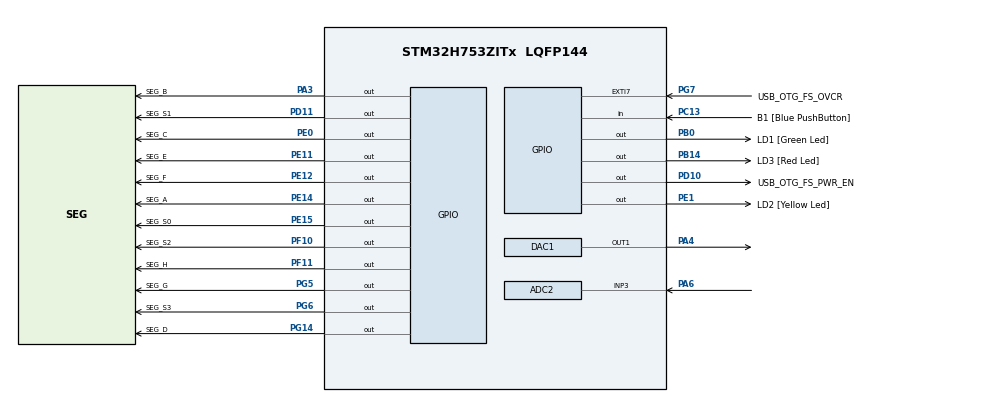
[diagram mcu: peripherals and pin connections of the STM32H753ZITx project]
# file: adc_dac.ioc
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ADC2.Channel-0\#ChannelRegularConversion=ADC_CHANNEL_3
ADC2.ExternalTrigConv=ADC_EXTERNALTRIG_T1_TRGO
ADC2.NbrOfConversionFlag=1
ADC2.OffsetNumber-0\#ChannelRegularConversion=ADC_OFFSET_NONE
ADC2.OffsetSignedSaturation-0\#ChannelRegularConversion=DISABLE
ADC2.Rank-0\#ChannelRegularConversion=1
ADC2.SamplingTime-0\#ChannelRegularConversion=ADC_SAMPLETIME_64CYCLES_5
CORTEX_M7.CPU_DCache=Disabled
CORTEX_M7.CPU_ICache=Disabled
CORTEX_M7.MPU_Control=__NULL
CORTEX_M7.default_mode_Activation=0
DAC1.DAC_Channel-DAC_OUT1=DAC_CHANNEL_1
Mcu.Family=STM32H7
Mcu.Name=STM32H753ZITx
Mcu.Package=LQFP144
NVIC.ADC_IRQn=true\:0\:0\:false\:false\:true\:true\:true\:true
NVIC.PriorityGroup=NVIC_PRIORITYGROUP_4
PA1.Signal=ETH_REF_CLK
PA11.Signal=USB_OTG_FS_DM
PA12.Signal=USB_OTG_FS_DP
PA2.Signal=ETH_MDIO
PA3.GPIO_Label=SEG_B
PA3.Signal=GPIO_Output
PA4.Signal=COMP_DAC11_group
PA6.Signal=ADCx_INP3
PA7.Signal=ETH_CRS_DV
PA8.Signal=USB_OTG_FS_SOF
PA9.Signal=USB_OTG_FS_VBUS
PB0.GPIO_Label=LD1 [Green Led]
PB0.Signal=GPIO_Output
PB13.Signal=ETH_TXD1
PB14.GPIO_Label=LD3 [Red Led]
PB14.Signal=GPIO_Output
PC1.Signal=ETH_MDC
PC13.GPIO_Label=B1 [Blue PushButton]
PC13.Signal=GPIO_Input
PC14-OSC32_IN\ (OSC32_IN).Mode=LSE-External-Oscillator
PC14-OSC32_IN\ (OSC32_IN).Signal=RCC_OSC32_IN
PC15-OSC32_OUT\ (OSC32_OUT).Mode=LSE-External-Oscillator
PC15-OSC32_OUT\ (OSC32_OUT).Signal=RCC_OSC32_OUT
PC4.Signal=ETH_RXD0
PC5.Signal=ETH_RXD1
PD10.GPIO_Label=USB_OTG_FS_PWR_EN
PD10.Signal=GPIO_Output
PD11.GPIO_Label=SEG_S1
PD11.Signal=GPIO_Output
PD8.GPIO_Label=STLINK_RX
PD8.Signal=USART3_TX
PD9.GPIO_Label=STLINK_TX
PD9.Signal=USART3_RX
PE0.GPIO_Label=SEG_C
PE0.Signal=GPIO_Output
PE1.GPIO_Label=LD2 [Yellow Led]
PE1.Signal=GPIO_Output
PE11.GPIO_Label=SEG_E
PE11.Signal=GPIO_Output
PE12.GPIO_Label=SEG_F
PE12.Signal=GPIO_Output
PE14.GPIO_Label=SEG_A
PE14.Signal=GPIO_Output
PE15.GPIO_Label=SEG_S0
PE15.Signal=GPIO_Output
PF10.GPIO_Label=SEG_S2
PF10.Signal=GPIO_Output
PF11.GPIO_Label=SEG_H
PF11.Signal=GPIO_Output
PG11.Signal=ETH_TX_EN
PG13.Signal=ETH_TXD0
PG14.GPIO_Label=SEG_D
PG14.Signal=GPIO_Output
PG5.GPIO_Label=SEG_G
PG5.Signal=GPIO_Output
PG6.GPIO_Label=SEG_S3
PG6.Signal=GPIO_Output
PG7.GPIO_Label=USB_OTG_FS_OVCR
PG7.Signal=GPXTI7
PH0-OSC_IN\ (PH0).Mode=HSE-External-Clock-Source
PH0-OSC_IN\ (PH0).Signal=RCC_OSC_IN
PH1-OSC_OUT\ (PH1).Signal=RCC_OSC_OUT
ProjectManager.HeapSize=0x200
ProjectManager.StackSize=0x400
ProjectManager.TargetToolchain=STM32CubeIDE
RCC.ADCFreq_Value=80000000
RCC.APB1Freq_Value=100000000
RCC.APB2Freq_Value=100000000
RCC.APB3Freq_Value=100000000
RCC.APB4Freq_Value=100000000
RCC.CortexFreq_Value=200000000
RCC.D1PPRE=RCC_APB3_DIV2
RCC.D2PPRE1=RCC_APB1_DIV2
RCC.D2PPRE2=RCC_APB2_DIV2
RCC.D3PPRE=RCC_APB4_DIV2
RCC.DIVM1=4
RCC.DIVM2=4
RCC.DIVN1=25
RCC.DIVN2=10
RCC.HCLKFreq_Value=200000000
RCC.PLL2FRACN=0
RCC.PLL3FRACN=0
RCC.PLLFRACN=0
RCC.PWR_Regulator_Voltage_Scale=PWR_REGULATOR_VOLTAGE_SCALE2
RCC.SYSCLKFreq_VALUE=200000000
RCC.SYSCLKSource=RCC_SYSCLKSOURCE_PLLCLK
RCC.USBFreq_Value=200000000
SH.ADCx_INP3.0=ADC2_INP3,IN3-Single-Ended
SH.COMP_DAC11_group.0=DAC1_OUT1,DAC_OUT1
TIM1.AutoReloadPreload=TIM_AUTORELOAD_PRELOAD_ENABLE
TIM1.Channel-Output\ Compare1\ No\ Output=TIM_CHANNEL_1
TIM1.Period=10
TIM1.Prescaler=64000
TIM1.TIM_MasterOutputTrigger=TIM_TRGO_UPDATE
VP_MEMORYMAP_VS_MEMORYMAP.Mode=CurAppReg
VP_TIM1_VS_ClockSourceINT.Mode=Internal
VP_TIM1_VS_no_output1.Mode=Output Compare1 No Output
board=custom

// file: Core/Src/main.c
/* USER CODE BEGIN Header */
/**
  ******************************************************************************
  * @file           : main.c
  * @brief          : Main program body
  ******************************************************************************
  * @attention
  *
  * Copyright (c) 2024 STMicroelectronics.
  * All rights reserved.
  *
  * This software is licensed under terms that can be found in the LICENSE file
  * in the root directory of this software component.
  * If no LICENSE file comes with this software, it is provided AS-IS.
  *
  ******************************************************************************
  */
/* USER CODE END Header */
#include "main.h"

/* USER CODE BEGIN Includes */
#include "segment.h"
/* USER CODE END Includes */

ADC_HandleTypeDef hadc2;

DAC_HandleTypeDef hdac1;

TIM_HandleTypeDef htim1;

/* USER CODE BEGIN PV */
segment_t *seg_handle;
/* USER CODE END PV */

void SystemClock_Config(void);
static void MX_GPIO_Init(void);
static void MX_ADC2_Init(void);
static void MX_DAC1_Init(void);
static void MX_TIM1_Init(void);

int main(void)
{

  /* MCU Configuration--------------------------------------------------------*/

  /* Reset of all peripherals, Initializes the Flash interface and the Systick. */
  HAL_Init();

  /* Configure the system clock */
  SystemClock_Config();

  /* Initialize all configured peripherals */
  MX_GPIO_Init();
  MX_ADC2_Init();
  MX_DAC1_Init();
  MX_TIM1_Init();
  /* USER CODE BEGIN 2 */
  //開啟ADC 功能
  HAL_ADC_Start_IT(&hadc2);
  //開啟PWM 作為ADC 觸發源
  HAL_TIM_PWM_Start(&htim1, TIM_CHANNEL_1);
  //設定七段顯示器顯示ADC 值
  seg_handle = segment_new(4);
  segment_num_set(seg_handle, 0);
  /* USER CODE END 2 */

  /* Infinite loop */
  while (1)
  {

    /* USER CODE BEGIN 3 */
	  __disable_irq();
	  segment_flush(seg_handle);
	  __enable_irq();
	  HAL_Delay(3);
  }
  /* USER CODE END 3 */
}

void SystemClock_Config(void)
{
  RCC_OscInitTypeDef RCC_OscInitStruct = {0};
  RCC_ClkInitTypeDef RCC_ClkInitStruct = {0};

  /** Supply configuration update enable
  */
  HAL_PWREx_ConfigSupply(PWR_LDO_SUPPLY);

  /** Configure the main internal regulator output voltage
  */
  __HAL_PWR_VOLTAGESCALING_CONFIG(PWR_REGULATOR_VOLTAGE_SCALE2);

  while(!__HAL_PWR_GET_FLAG(PWR_FLAG_VOSRDY)) {}

  /** Initializes the RCC Oscillators according to the specified parameters
  * in the RCC_OscInitTypeDef structure.
  */
  RCC_OscInitStruct.OscillatorType = RCC_OSCILLATORTYPE_HSI;
  RCC_OscInitStruct.HSIState = RCC_HSI_DIV1;
  RCC_OscInitStruct.HSICalibrationValue = RCC_HSICALIBRATION_DEFAULT;
  RCC_OscInitStruct.PLL.PLLState = RCC_PLL_ON;
  RCC_OscInitStruct.PLL.PLLSource = RCC_PLLSOURCE_HSI;
  RCC_OscInitStruct.PLL.PLLM = 4;
  RCC_OscInitStruct.PLL.PLLN = 25;
  RCC_OscInitStruct.PLL.PLLP = 2;
  RCC_OscInitStruct.PLL.PLLQ = 2;
  RCC_OscInitStruct.PLL.PLLR = 2;
  RCC_OscInitStruct.PLL.PLLRGE = RCC_PLL1VCIRANGE_3;
  RCC_OscInitStruct.PLL.PLLVCOSEL = RCC_PLL1VCOWIDE;
  RCC_OscInitStruct.PLL.PLLFRACN = 0;
  if (HAL_RCC_OscConfig(&RCC_OscInitStruct) != HAL_OK)
  {
    Error_Handler();
  }

  /** Initializes the CPU, AHB and APB buses clocks
  */
  RCC_ClkInitStruct.ClockType = RCC_CLOCKTYPE_HCLK|RCC_CLOCKTYPE_SYSCLK
                              |RCC_CLOCKTYPE_PCLK1|RCC_CLOCKTYPE_PCLK2
                              |RCC_CLOCKTYPE_D3PCLK1|RCC_CLOCKTYPE_D1PCLK1;
  RCC_ClkInitStruct.SYSCLKSource = RCC_SYSCLKSOURCE_PLLCLK;
  RCC_ClkInitStruct.SYSCLKDivider = RCC_SYSCLK_DIV1;
  RCC_ClkInitStruct.AHBCLKDivider = RCC_HCLK_DIV1;
  RCC_ClkInitStruct.APB3CLKDivider = RCC_APB3_DIV2;
  RCC_ClkInitStruct.APB1CLKDivider = RCC_APB1_DIV2;
  RCC_ClkInitStruct.APB2CLKDivider = RCC_APB2_DIV2;
  RCC_ClkInitStruct.APB4CLKDivider = RCC_APB4_DIV2;

  if (HAL_RCC_ClockConfig(&RCC_ClkInitStruct, FLASH_LATENCY_3) != HAL_OK)
  {
    Error_Handler();
  }
}

static void MX_ADC2_Init(void)
{

  ADC_ChannelConfTypeDef sConfig = {0};

  /** Common config
  */
  hadc2.Instance = ADC2;
  hadc2.Init.ScanConvMode = ADC_SCAN_DISABLE;
  hadc2.Init.EOCSelection = ADC_EOC_SINGLE_CONV;
  hadc2.Init.LowPowerAutoWait = DISABLE;
  hadc2.Init.ContinuousConvMode = DISABLE;
  hadc2.Init.NbrOfConversion = 1;
  hadc2.Init.DiscontinuousConvMode = DISABLE;
  hadc2.Init.ExternalTrigConv = ADC_EXTERNALTRIG_T1_TRGO;
  hadc2.Init.ExternalTrigConvEdge = ADC_EXTERNALTRIGCONVEDGE_RISING;
  hadc2.Init.ConversionDataManagement = ADC_CONVERSIONDATA_DR;
  hadc2.Init.Overrun = ADC_OVR_DATA_PRESERVED;
  hadc2.Init.LeftBitShift = ADC_LEFTBITSHIFT_NONE;
  hadc2.Init.OversamplingMode = DISABLE;
  hadc2.Init.Oversampling.Ratio = 1;
  if (HAL_ADC_Init(&hadc2) != HAL_OK)
  {
    Error_Handler();
  }
  hadc2.Init.ClockPrescaler = ADC_CLOCK_ASYNC_DIV8;
  hadc2.Init.Resolution = ADC_RESOLUTION_16B;
  if (HAL_ADC_Init(&hadc2) != HAL_OK)
  {
    Error_Handler();
  }

  /** Configure Regular Channel
  */
  sConfig.Channel = ADC_CHANNEL_3;
  sConfig.Rank = ADC_REGULAR_RANK_1;
  sConfig.SamplingTime = ADC_SAMPLETIME_64CYCLES_5;
  sConfig.SingleDiff = ADC_SINGLE_ENDED;
  sConfig.OffsetNumber = ADC_OFFSET_NONE;
  sConfig.Offset = 0;
  sConfig.OffsetSignedSaturation = DISABLE;
  if (HAL_ADC_ConfigChannel(&hadc2, &sConfig) != HAL_OK)
  {
    Error_Handler();
  }

}

static void MX_DAC1_Init(void)
{

  DAC_ChannelConfTypeDef sConfig = {0};

  /** DAC Initialization
  */
  hdac1.Instance = DAC1;
  if (HAL_DAC_Init(&hdac1) != HAL_OK)
  {
    Error_Handler();
  }

  /** DAC channel OUT1 config
  */
  sConfig.DAC_SampleAndHold = DAC_SAMPLEANDHOLD_DISABLE;
  sConfig.DAC_Trigger = DAC_TRIGGER_NONE;
  sConfig.DAC_OutputBuffer = DAC_OUTPUTBUFFER_ENABLE;
  sConfig.DAC_ConnectOnChipPeripheral = DAC_CHIPCONNECT_DISABLE;
  sConfig.DAC_UserTrimming = DAC_TRIMMING_FACTORY;
  if (HAL_DAC_ConfigChannel(&hdac1, &sConfig, DAC_CHANNEL_1) != HAL_OK)
  {
    Error_Handler();
  }

}

static void MX_TIM1_Init(void)
{

  TIM_ClockConfigTypeDef sClockSourceConfig = {0};
  TIM_MasterConfigTypeDef sMasterConfig = {0};
  TIM_OC_InitTypeDef sConfigOC = {0};
  TIM_BreakDeadTimeConfigTypeDef sBreakDeadTimeConfig = {0};

  htim1.Instance = TIM1;
  htim1.Init.Prescaler = 64000;
  htim1.Init.CounterMode = TIM_COUNTERMODE_UP;
  htim1.Init.Period = 10;
  htim1.Init.ClockDivision = TIM_CLOCKDIVISION_DIV1;
  htim1.Init.RepetitionCounter = 0;
  htim1.Init.AutoReloadPreload = TIM_AUTORELOAD_PRELOAD_ENABLE;
  if (HAL_TIM_Base_Init(&htim1) != HAL_OK)
  {
    Error_Handler();
  }
  sClockSourceConfig.ClockSource = TIM_CLOCKSOURCE_INTERNAL;
  if (HAL_TIM_ConfigClockSource(&htim1, &sClockSourceConfig) != HAL_OK)
  {
    Error_Handler();
  }
  if (HAL_TIM_OC_Init(&htim1) != HAL_OK)
  {
    Error_Handler();
  }
  sMasterConfig.MasterOutputTrigger = TIM_TRGO_UPDATE;
  sMasterConfig.MasterOutputTrigger2 = TIM_TRGO2_RESET;
  sMasterConfig.MasterSlaveMode = TIM_MASTERSLAVEMODE_DISABLE;
  if (HAL_TIMEx_MasterConfigSynchronization(&htim1, &sMasterConfig) != HAL_OK)
  {
    Error_Handler();
  }
  sConfigOC.OCMode = TIM_OCMODE_TIMING;
  sConfigOC.Pulse = 0;
  sConfigOC.OCPolarity = TIM_OCPOLARITY_HIGH;
  sConfigOC.OCNPolarity = TIM_OCNPOLARITY_HIGH;
  sConfigOC.OCFastMode = TIM_OCFAST_DISABLE;
  sConfigOC.OCIdleState = TIM_OCIDLESTATE_RESET;
  sConfigOC.OCNIdleState = TIM_OCNIDLESTATE_RESET;
  if (HAL_TIM_OC_ConfigChannel(&htim1, &sConfigOC, TIM_CHANNEL_1) != HAL_OK)
  {
    Error_Handler();
  }
  sBreakDeadTimeConfig.OffStateRunMode = TIM_OSSR_DISABLE;
  sBreakDeadTimeConfig.OffStateIDLEMode = TIM_OSSI_DISABLE;
  sBreakDeadTimeConfig.LockLevel = TIM_LOCKLEVEL_OFF;
  sBreakDeadTimeConfig.DeadTime = 0;
  sBreakDeadTimeConfig.BreakState = TIM_BREAK_DISABLE;
  sBreakDeadTimeConfig.BreakPolarity = TIM_BREAKPOLARITY_HIGH;
  sBreakDeadTimeConfig.BreakFilter = 0;
  sBreakDeadTimeConfig.Break2State = TIM_BREAK2_DISABLE;
  sBreakDeadTimeConfig.Break2Polarity = TIM_BREAK2POLARITY_HIGH;
  sBreakDeadTimeConfig.Break2Filter = 0;
  sBreakDeadTimeConfig.AutomaticOutput = TIM_AUTOMATICOUTPUT_DISABLE;
  if (HAL_TIMEx_ConfigBreakDeadTime(&htim1, &sBreakDeadTimeConfig) != HAL_OK)
  {
    Error_Handler();
  }

}

static void MX_GPIO_Init(void)
{
  GPIO_InitTypeDef GPIO_InitStruct = {0};

  /* GPIO Ports Clock Enable */
  __HAL_RCC_GPIOC_CLK_ENABLE();
  __HAL_RCC_GPIOF_CLK_ENABLE();
  __HAL_RCC_GPIOH_CLK_ENABLE();
  __HAL_RCC_GPIOA_CLK_ENABLE();
  __HAL_RCC_GPIOB_CLK_ENABLE();
  __HAL_RCC_GPIOE_CLK_ENABLE();
  __HAL_RCC_GPIOD_CLK_ENABLE();
  __HAL_RCC_GPIOG_CLK_ENABLE();

  /*Configure GPIO pin Output Level */
  HAL_GPIO_WritePin(GPIOF, SEG_S2_Pin|SEG_H_Pin, GPIO_PIN_RESET);

  /*Configure GPIO pin Output Level */
  HAL_GPIO_WritePin(SEG_B_GPIO_Port, SEG_B_Pin, GPIO_PIN_RESET);

  /*Configure GPIO pin Output Level */
  HAL_GPIO_WritePin(GPIOB, LD1_Pin|LD3_Pin, GPIO_PIN_RESET);

  /*Configure GPIO pin Output Level */
  HAL_GPIO_WritePin(GPIOE, SEG_E_Pin|SEG_F_Pin|SEG_A_Pin|SEG_S0_Pin
                          |SEG_C_Pin|LD2_Pin, GPIO_PIN_RESET);

  /*Configure GPIO pin Output Level */
  HAL_GPIO_WritePin(GPIOD, USB_OTG_FS_PWR_EN_Pin|SEG_S1_Pin, GPIO_PIN_RESET);

  /*Configure GPIO pin Output Level */
  HAL_GPIO_WritePin(GPIOG, SEG_G_Pin|SEG_S3_Pin|SEG_D_Pin, GPIO_PIN_RESET);

  /*Configure GPIO pin : B1_Pin */
  GPIO_InitStruct.Pin = B1_Pin;
  GPIO_InitStruct.Mode = GPIO_MODE_INPUT;
  GPIO_InitStruct.Pull = GPIO_NOPULL;
  HAL_GPIO_Init(B1_GPIO_Port, &GPIO_InitStruct);

  /*Configure GPIO pins : SEG_S2_Pin SEG_H_Pin */
  GPIO_InitStruct.Pin = SEG_S2_Pin|SEG_H_Pin;
  GPIO_InitStruct.Mode = GPIO_MODE_OUTPUT_PP;
  GPIO_InitStruct.Pull = GPIO_NOPULL;
  GPIO_InitStruct.Speed = GPIO_SPEED_FREQ_LOW;
  HAL_GPIO_Init(GPIOF, &GPIO_InitStruct);

  /*Configure GPIO pins : PC1 PC4 PC5 */
  GPIO_InitStruct.Pin = GPIO_PIN_1|GPIO_PIN_4|GPIO_PIN_5;
  GPIO_InitStruct.Mode = GPIO_MODE_AF_PP;
  GPIO_InitStruct.Pull = GPIO_NOPULL;
  GPIO_InitStruct.Speed = GPIO_SPEED_FREQ_LOW;
  GPIO_InitStruct.Alternate = GPIO_AF11_ETH;
  HAL_GPIO_Init(GPIOC, &GPIO_InitStruct);

  /*Configure GPIO pins : PA1 PA2 PA7 */
  GPIO_InitStruct.Pin = GPIO_PIN_1|GPIO_PIN_2|GPIO_PIN_7;
  GPIO_InitStruct.Mode = GPIO_MODE_AF_PP;
  GPIO_InitStruct.Pull = GPIO_NOPULL;
  GPIO_InitStruct.Speed = GPIO_SPEED_FREQ_LOW;
  GPIO_InitStruct.Alternate = GPIO_AF11_ETH;
  HAL_GPIO_Init(GPIOA, &GPIO_InitStruct);

  /*Configure GPIO pin : SEG_B_Pin */
  GPIO_InitStruct.Pin = SEG_B_Pin;
  GPIO_InitStruct.Mode = GPIO_MODE_OUTPUT_PP;
  GPIO_InitStruct.Pull = GPIO_NOPULL;
  GPIO_InitStruct.Speed = GPIO_SPEED_FREQ_LOW;
  HAL_GPIO_Init(SEG_B_GPIO_Port, &GPIO_InitStruct);

  /*Configure GPIO pins : LD1_Pin LD3_Pin */
  GPIO_InitStruct.Pin = LD1_Pin|LD3_Pin;
  GPIO_InitStruct.Mode = GPIO_MODE_OUTPUT_PP;
  GPIO_InitStruct.Pull = GPIO_NOPULL;
  GPIO_InitStruct.Speed = GPIO_SPEED_FREQ_LOW;
  HAL_GPIO_Init(GPIOB, &GPIO_InitStruct);

  /*Configure GPIO pins : SEG_E_Pin SEG_F_Pin SEG_A_Pin SEG_S0_Pin
                           SEG_C_Pin LD2_Pin */
  GPIO_InitStruct.Pin = SEG_E_Pin|SEG_F_Pin|SEG_A_Pin|SEG_S0_Pin
                          |SEG_C_Pin|LD2_Pin;
  GPIO_InitStruct.Mode = GPIO_MODE_OUTPUT_PP;
  GPIO_InitStruct.Pull = GPIO_NOPULL;
  GPIO_InitStruct.Speed = GPIO_SPEED_FREQ_LOW;
  HAL_GPIO_Init(GPIOE, &GPIO_InitStruct);

  /*Configure GPIO pin : PB13 */
  GPIO_InitStruct.Pin = GPIO_PIN_13;
  GPIO_InitStruct.Mode = GPIO_MODE_AF_PP;
  GPIO_InitStruct.Pull = GPIO_NOPULL;
  GPIO_InitStruct.Speed = GPIO_SPEED_FREQ_LOW;
  GPIO_InitStruct.Alternate = GPIO_AF11_ETH;
  HAL_GPIO_Init(GPIOB, &GPIO_InitStruct);

  /*Configure GPIO pins : STLINK_RX_Pin STLINK_TX_Pin */
  GPIO_InitStruct.Pin = STLINK_RX_Pin|STLINK_TX_Pin;
  GPIO_InitStruct.Mode = GPIO_MODE_AF_PP;
  GPIO_InitStruct.Pull = GPIO_NOPULL;
  GPIO_InitStruct.Speed = GPIO_SPEED_FREQ_LOW;
  GPIO_InitStruct.Alternate = GPIO_AF7_USART3;
  HAL_GPIO_Init(GPIOD, &GPIO_InitStruct);

  /*Configure GPIO pins : USB_OTG_FS_PWR_EN_Pin SEG_S1_Pin */
  GPIO_InitStruct.Pin = USB_OTG_FS_PWR_EN_Pin|SEG_S1_Pin;
  GPIO_InitStruct.Mode = GPIO_MODE_OUTPUT_PP;
  GPIO_InitStruct.Pull = GPIO_NOPULL;
  GPIO_InitStruct.Speed = GPIO_SPEED_FREQ_LOW;
  HAL_GPIO_Init(GPIOD, &GPIO_InitStruct);

  /*Configure GPIO pins : SEG_G_Pin SEG_S3_Pin SEG_D_Pin */
  GPIO_InitStruct.Pin = SEG_G_Pin|SEG_S3_Pin|SEG_D_Pin;
  GPIO_InitStruct.Mode = GPIO_MODE_OUTPUT_PP;
  GPIO_InitStruct.Pull = GPIO_NOPULL;
  GPIO_InitStruct.Speed = GPIO_SPEED_FREQ_LOW;
  HAL_GPIO_Init(GPIOG, &GPIO_InitStruct);

  /*Configure GPIO pin : USB_OTG_FS_OVCR_Pin */
  GPIO_InitStruct.Pin = USB_OTG_FS_OVCR_Pin;
  GPIO_InitStruct.Mode = GPIO_MODE_IT_RISING;
  GPIO_InitStruct.Pull = GPIO_NOPULL;
  HAL_GPIO_Init(USB_OTG_FS_OVCR_GPIO_Port, &GPIO_InitStruct);

  /*Configure GPIO pins : PA8 PA11 PA12 */
  GPIO_InitStruct.Pin = GPIO_PIN_8|GPIO_PIN_11|GPIO_PIN_12;
  GPIO_InitStruct.Mode = GPIO_MODE_AF_PP;
  GPIO_InitStruct.Pull = GPIO_NOPULL;
  GPIO_InitStruct.Speed = GPIO_SPEED_FREQ_LOW;
  GPIO_InitStruct.Alternate = GPIO_AF10_OTG1_FS;
  HAL_GPIO_Init(GPIOA, &GPIO_InitStruct);

  /*Configure GPIO pins : PG11 PG13 */
  GPIO_InitStruct.Pin = GPIO_PIN_11|GPIO_PIN_13;
  GPIO_InitStruct.Mode = GPIO_MODE_AF_PP;
  GPIO_InitStruct.Pull = GPIO_NOPULL;
  GPIO_InitStruct.Speed = GPIO_SPEED_FREQ_LOW;
  GPIO_InitStruct.Alternate = GPIO_AF11_ETH;
  HAL_GPIO_Init(GPIOG, &GPIO_InitStruct);

}

/* USER CODE BEGIN 4 */

void HAL_ADC_ConvCpltCallback(ADC_HandleTypeDef *hadc) {
	uint32_t val = HAL_ADC_GetValue(&hadc2);
	val = val * 3300 / 65535;
	segment_num_set(seg_handle, val);
}
/* USER CODE END 4 */

void Error_Handler(void)
{
  __disable_irq();
  while (1)
  {
  }
}
